# LPC55S6x register map
Vendor: nxp.com; File version: 1.0
CPU: CM33 r2p0, little endian, MPU, FPU, VTOR, 3 interrupt priority bits
Registers are 32-bit, read-write, reset 0x0 unless marked. A register's access mark holds for its fields unless they carry their own. Offsets are from the block's base; [hi:lo] are bit positions; {n}, {i} and the like mark numbered series.

## SYSCTL — system controller
Base 0x40023000
0x00 UPDATELCKOUT — update lock out control
  [0] UPDATELCKOUT — All Registers
    0=NORMAL_MODE (Normal Mode. Can be written to.); 1=PROTECTED_MODE (Protected Mode. Cannot be written to.)
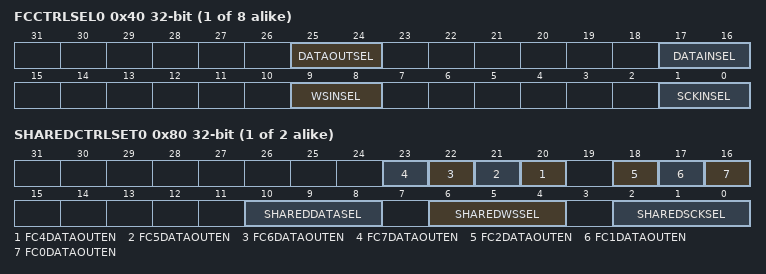
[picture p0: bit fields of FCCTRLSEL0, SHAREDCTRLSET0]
{0x40+4i} FCCTRLSEL{i} (i=0..7) — Selects the source for SCK going into Flexcomm 0
  [25:24] DATAOUTSEL — Selects the source for DATA output from this Flexcomm.
    0=ORIG_FLEX_I2S_SIGNALS (Selects the dedicated FCn_RXD_SDA_MOSI_DATA output from this Flexcomm.); 1=SHARED_SET0_I2S_SIGNALS (Output data is taken from shared signal set 0 (defined by SHAREDCTRLSET0).); 2=SHARED_SET1_I2S_SIGNALS (Output data is taken from shared signal set 1 (defined by SHAREDCTRLSET1).)
  [17:16] DATAINSEL — Selects the source for DATA input to this Flexcomm.
    0=ORIG_FLEX_I2S_SIGNALS (Selects the dedicated FCn_RXD_SDA_MOSI_DATA input for this Flexcomm.); 1=SHARED_SET0_I2S_SIGNALS (Input data is taken from shared signal set 0 (defined by SHAREDCTRLSET0).); 2=SHARED_SET1_I2S_SIGNALS (Input data is taken from shared signal set 1 (defined by SHAREDCTRLSET1).)
  [9:8] WSINSEL — Selects the source for WS going into this Flexcomm.
    0=ORIG_FLEX_I2S_SIGNALS (Selects the dedicated (FCn_TXD_SCL_MISO_WS) function for this Flexcomm.); 1=SHARED_SET0_I2S_SIGNALS (WS is taken from shared signal set 0 (defined by SHAREDCTRLSET0).); 2=SHARED_SET1_I2S_SIGNALS (WS is taken from shared signal set 1 (defined by SHAREDCTRLSET1).)
  [1:0] SCKINSEL rw-once — Selects the source for SCK going into this Flexcomm.
    0=ORIG_FLEX_I2S_SIGNALS (Selects the dedicated FCn_SCK function for this Flexcomm.); 1=SHARED_SET0_I2S_SIGNALS (SCK is taken from shared signal set 0 (defined by SHAREDCTRLSET0).); 2=SHARED_SET1_I2S_SIGNALS (SCK is taken from shared signal set 1 (defined by SHAREDCTRLSET1).)
{0x80+4i} SHAREDCTRLSET{i} (i=0..1) — Selects sources and data combinations for shared signal set 0.
  [n+16] FC{n}DATAOUTEN (n=4..7) — Controls FC{n} contribution to SHAREDDATAOUT for this shared set.
    0=INPUT (Data output from FC{n} does not contribute to this shared set.); 1=OUTPUT (Data output from FC{n} does contribute to this shared set.)
  [18] FC2DATAOUTEN — Controls FC2 contribution to SHAREDDATAOUT for this shared set.
    0=INPUT (Data output from FC2 does not contribute to this shared set.); 1=OUTPUT (Data output from FC2 does contribute to this shared set.)
  [17] FC1DATAOUTEN — Controls FC1 contribution to SHAREDDATAOUT for this shared set.
    0=INPUT (Data output from FC1 does not contribute to this shared set.); 1=OUTPUT (Data output from FC1 does contribute to this shared set.)
  [16] FC0DATAOUTEN — Controls FC0 contribution to SHAREDDATAOUT for this shared set.
    0=INPUT (Data output from FC0 does not contribute to this shared set.); 1=OUTPUT (Data output from FC0 does contribute to this shared set.)
  [10:8] SHAREDDATASEL — Selects the source for DATA input for this shared signal set.
    {v}=FLEXCOMM{v} (DATA input for this shared signal set comes from Flexcomm {v}.) (v=0..7)
  [6:4] SHAREDWSSEL — Selects the source for WS of this shared signal set.
    {v}=FLEXCOMM{v} (WS for this shared signal set comes from Flexcomm {v}.) (v=0..7)
  [2:0] SHAREDSCKSEL — Selects the source for SCK of this shared signal set.
    {v}=FLEXCOMM{v} (SCK for this shared signal set comes from Flexcomm {v}.) (v=0..7)
0x100 USB_HS_STATUS (reset mask 0x1C0FF00) — Status register for USB HS
  [0] USBHS_3V_NOK ro — USB_HS: Low voltage detection on 3.3V supply.
    0=SUPPLY_3V_OK (3v3 supply is good.); 1=SUPPLY_3V_LOW (3v3 supply is too low.)

## OSTIMER — Synchronous OS/Event timer with Wakeup Timer
Base 0x4002D000
0x00 EVTIMERL ro — EVTIMER Low Register
  [31:0] EVTIMER_COUNT_VALUE — A read reflects the current value of the lower 32 bits of the EVTIMER. Note there is physically only one EVTimer, readable from all domains.
0x04 EVTIMERH — EVTIMER High Register
  [9:0] EVTIMER_COUNT_VALUE ro — A read reflects the current value of the upper 32 bits of the EVTIMER. Note there is physically only one EVTimer, readable from all domains.
0x08 CAPTUREn_L ro — Local Capture Low Register for CPUn
  [31:0] CAPTUREn_VALUE — A read reflects the value of the lower 32 bits of the central EVTIMER at the time the last capture signal was generated by the CPU. A separate pair of CAPTURE registers are implemented for each CPU. Each CPU reads its own capture value at the same pair of addresses.
0x0C CAPTUREn_H — Local Capture High Register for CPUn
  [9:0] CAPTUREn_VALUE ro — A read reflects the value of the upper 32 bits of the central EVTIMER at the time the last capture signal was generated by the CPU. A separate pair of CAPTURE registers are implemented for each CPU. Each CPU reads its own capture value at the same pair of addresses.
0x10 MATCHn_L — Local Match Low Register for CPUn
  [31:0] MATCHn_VALUE — The value written to the MATCH (L/H) register pair is compared against the central EVTIMER. When a match occurs, an interrupt request is generated if enabled. A separate pair of MATCH registers are implemented for each CPU. Each CPU reads its own local value at the same pair of addresses.
0x14 MATCHn_H — Match High Register for CPUn
  [9:0] MATCHn_VALUE — The value written to the MATCH (L/H) register pair is compared against the central EVTIMER. When a match occurs, an interrupt request is generated if enabled. A separate pair of MATCH registers are implemented for each CPU. Each CPU reads its own local value at the same pair of addresses.
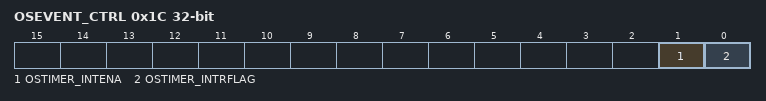
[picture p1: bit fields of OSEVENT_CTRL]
0x1C OSEVENT_CTRL — OS_EVENT TIMER Control Register for CPUn
  [1] OSTIMER_INTENA — When this bit is '1' an interrupt/wakeup request to the Domainn processor will be asserted when the OSTIMER_INTR flag is set. When this bit is '0', interrupt/wakeup requests due to the OSTIMER_INTR flag are blocked.A separate OSEVENT_CTRL register is implemented for each CPU. Each CPU reads its own local value at the same address.
  [0] OSTIMER_INTRFLAG — This bit is set when a match occurs between the central 64-bit EVTIMER and the value programmed in the Match-register pair for the associated CPU This bit is cleared by writing a '1'. Writes to clear this bit are asynchronous. This should be done before a new match value is written into the MATCH_L/H registers
